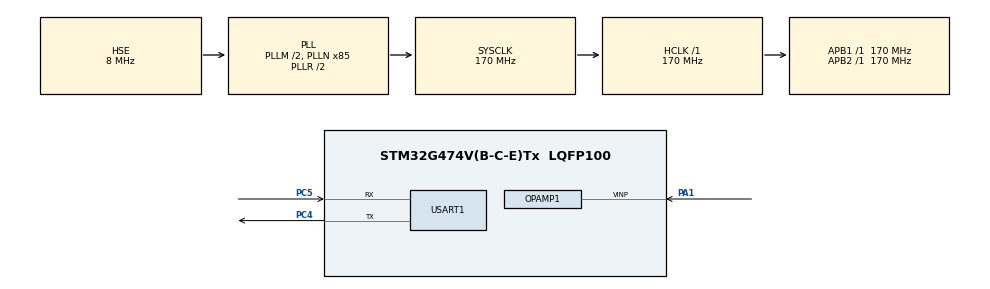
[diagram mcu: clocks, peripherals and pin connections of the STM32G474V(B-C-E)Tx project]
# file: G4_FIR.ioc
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ADC1.Channel-0\#ChannelRegularConversion=ADC_CHANNEL_VOPAMP1
ADC1.DMAContinuousRequests=ENABLE
ADC1.ExternalTrigConv=ADC_EXTERNALTRIG_T3_TRGO
ADC1.NbrOfConversionFlag=1
ADC1.OffsetNumber-0\#ChannelRegularConversion=ADC_OFFSET_NONE
ADC1.Rank-0\#ChannelRegularConversion=1
ADC1.SamplingTime-0\#ChannelRegularConversion=ADC_SAMPLETIME_2CYCLES_5
ADC1.master=1
Dma.ADC1.0.Direction=DMA_PERIPH_TO_MEMORY
Dma.ADC1.0.EventEnable=DISABLE
Dma.ADC1.0.Instance=DMA1_Channel1
Dma.ADC1.0.MemDataAlignment=DMA_MDATAALIGN_HALFWORD
Dma.ADC1.0.MemInc=DMA_MINC_ENABLE
Dma.ADC1.0.Mode=DMA_NORMAL
Dma.ADC1.0.PeriphDataAlignment=DMA_PDATAALIGN_HALFWORD
Dma.ADC1.0.PeriphInc=DMA_PINC_DISABLE
Dma.ADC1.0.Polarity=HAL_DMAMUX_REQ_GEN_RISING
Dma.ADC1.0.Priority=DMA_PRIORITY_LOW
Dma.ADC1.0.RequestNumber=1
Dma.ADC1.0.SignalID=NONE
Dma.ADC1.0.SyncEnable=DISABLE
Dma.ADC1.0.SyncPolarity=HAL_DMAMUX_SYNC_NO_EVENT
Dma.ADC1.0.SyncRequestNumber=1
Dma.ADC1.0.SyncSignalID=NONE
Dma.Request0=ADC1
Mcu.Family=STM32G4
Mcu.Name=STM32G474V(B-C-E)Tx
Mcu.Package=LQFP100
NVIC.DMA1_Channel1_IRQn=true\:0\:0\:false\:false\:true\:false\:true
NVIC.PriorityGroup=NVIC_PRIORITYGROUP_4
PA1.Mode=Follower_Internally_Connected
PA1.Signal=OPAMP1_VINP
PA13.Mode=Serial_Wire
PA13.Signal=SYS_JTMS-SWDIO
PA14.Mode=Serial_Wire
PA14.Signal=SYS_JTCK-SWCLK
PC14-OSC32_IN.Mode=LSE-External-Oscillator
PC14-OSC32_IN.Signal=RCC_OSC32_IN
PC15-OSC32_OUT.Mode=LSE-External-Oscillator
PC15-OSC32_OUT.Signal=RCC_OSC32_OUT
PC4.Mode=Asynchronous
PC4.Signal=USART1_TX
PC5.Mode=Asynchronous
PC5.Signal=USART1_RX
PF0-OSC_IN.Mode=HSE-External-Oscillator
PF0-OSC_IN.Signal=RCC_OSC_IN
PF1-OSC_OUT.Mode=HSE-External-Oscillator
PF1-OSC_OUT.Signal=RCC_OSC_OUT
ProjectManager.HeapSize=0x200
ProjectManager.StackSize=0x400
ProjectManager.TargetToolchain=MDK-ARM V5.32
RCC.ADC12Freq_Value=170000000
RCC.ADC345Freq_Value=170000000
RCC.AHBFreq_Value=170000000
RCC.APB1Freq_Value=170000000
RCC.APB1TimFreq_Value=170000000
RCC.APB2Freq_Value=170000000
RCC.APB2TimFreq_Value=170000000
RCC.CortexFreq_Value=170000000
RCC.EXTERNAL_CLOCK_VALUE=12288000
RCC.HCLKFreq_Value=170000000
RCC.HSE_VALUE=8000000
RCC.HSI48_VALUE=48000000
RCC.HSI_VALUE=16000000
RCC.PLLM=RCC_PLLM_DIV2
RCC.PLLN=85
RCC.PLLSourceVirtual=RCC_PLLSOURCE_HSE
RCC.SYSCLKFreq_VALUE=170000000
RCC.SYSCLKSource=RCC_SYSCLKSOURCE_PLLCLK
RCC.USBFreq_Value=170000000
RCC.VCOOutputFreq_Value=340000000
STMicroelectronics.X-CUBE-ALGOBUILD.1.3.0.LibraryCcDSPOoLibraryJjDSPOoLibrary=true
TIM3.AutoReloadPreload=TIM_AUTORELOAD_PRELOAD_ENABLE
TIM3.PeriodNoDither=1
TIM3.TIM_MasterOutputTrigger=TIM_TRGO_UPDATE
USART1.VirtualMode-Asynchronous=VM_ASYNC
VP_ADC1_OPAMP_INTERNAL1.Mode=IN-OPAMP1
VP_STMicroelectronics.X-CUBE-ALGOBUILD_VS_DSPOoLibraryJjLibrary_1.3.0_1.3.0.Mode=DSPOoLibraryJjLibrary
VP_SYS_VS_DBSignals.Mode=DisableDeadBatterySignals
VP_TIM3_VS_ClockSourceINT.Mode=Internal
board=custom

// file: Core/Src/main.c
/* USER CODE BEGIN Header */
/**
  ******************************************************************************
  * @file           : main.c
  * @brief          : Main program body
  ******************************************************************************
  * @attention
  *
  * Copyright (c) 2022 STMicroelectronics.
  * All rights reserved.
  *
  * This software is licensed under terms that can be found in the LICENSE file
  * in the root directory of this software component.
  * If no LICENSE file comes with this software, it is provided AS-IS.
  *
  ******************************************************************************
  */
/* USER CODE END Header */
#include "main.h"
#include "adc.h"
#include "dma.h"
#include "opamp.h"
#include "tim.h"
#include "usart.h"
#include "gpio.h"

/* USER CODE BEGIN Includes */

#include "arm_math.h"
#include <stdio.h>
#include "delay.h"
#include "string.h"

/* USER CODE END Includes */

void SystemClock_Config(void);
/* USER CODE BEGIN PFP */
void uspp(uint16_t usa,char words[]);

/* USER CODE END PFP */

/* USER CODE BEGIN 0 */

float32_t DATA_IN[5000],DATA_INB[5000];
float32_t DATA_OUT[5000];
uint16_t DATA[5000];
char buffer[10];
int i;

arm_fir_instance_f32 S;

const float32_t B[101] = {
   0.001416345223328, 0.001435384422246, 0.001486642035499, 0.001570116626859,
   0.001685670771667, 0.001833031141338, 0.002011789176834, 0.002221402350021,
   0.002461196009159, 0.002730365802191, 0.003027980668889, 0.003352986390318,
   0.003704209681613, 0.004080362811548, 0.004480048730026, 0.004901766682266,
   0.005343918286277, 0.005804814048062, 0.006282680286986, 0.006775666441868,
   0.007281852726575, 0.007799258102288, 0.008325848532123, 0.008859545482467,
   0.009398234634226, 0.009939774766166,  0.01048200677172,  0.01102276276991,
     0.0115598752707,  0.01209118635454,    0.012614556826,  0.01312787530131,
     0.0136290671898,  0.01411610352987,  0.01458700964048,  0.01503987355008,
     0.0154728541657,  0.01588418914636,  0.01627220244564,  0.01663531149046,
    0.01697203396399,   0.0172809941628,  0.01756092890008,  0.01781069292876,
     0.0180292638604,  0.01821574655821,   0.0183693769845,  0.01848952548564,
    0.01857569949985,  0.01862754567586,  0.01864485139299,  0.01862754567586,
    0.01857569949985,  0.01848952548564,   0.0183693769845,  0.01821574655821,
     0.0180292638604,  0.01781069292876,  0.01756092890008,   0.0172809941628,
    0.01697203396399,  0.01663531149046,  0.01627220244564,  0.01588418914636,
     0.0154728541657,  0.01503987355008,  0.01458700964048,  0.01411610352987,
     0.0136290671898,  0.01312787530131,    0.012614556826,  0.01209118635454,
     0.0115598752707,  0.01102276276991,  0.01048200677172, 0.009939774766166,
   0.009398234634226, 0.008859545482467, 0.008325848532123, 0.007799258102288,
   0.007281852726575, 0.006775666441868, 0.006282680286986, 0.005804814048062,
   0.005343918286277, 0.004901766682266, 0.004480048730026, 0.004080362811548,
   0.003704209681613, 0.003352986390318, 0.003027980668889, 0.002730365802191,
   0.002461196009159, 0.002221402350021, 0.002011789176834, 0.001833031141338,
   0.001685670771667, 0.001570116626859, 0.001486642035499, 0.001435384422246,
   0.001416345223328
};

const int BL = 101;
float32_t pState[10000];

/* USER CODE END 0 */

int main(void)
{

  /* MCU Configuration--------------------------------------------------------*/

  /* Reset of all peripherals, Initializes the Flash interface and the Systick. */
  HAL_Init();

  /* Configure the system clock */
  SystemClock_Config();

  /* Initialize all configured peripherals */
  MX_GPIO_Init();
  MX_DMA_Init();
  MX_ADC1_Init();
  MX_OPAMP1_Init();
  MX_TIM3_Init();
  MX_USART1_UART_Init();
  /* USER CODE BEGIN 2 */

	Delay_Init(170);
	HAL_OPAMP_Start(&hopamp1);
	HAL_TIM_Base_Start(&htim3);
	HAL_ADC_Start_DMA(&hadc1,(uint32_t *)DATA,5000);
	Delay_ms(2000);
	for(i=0;i<5000;i++){
		DATA_IN[i]=((float32_t)DATA[i])/4095.0*3.3;
		sprintf(buffer,"%.2f",DATA_IN[i]*1000);
		uspp(1,buffer);
		uspp(1,"\r\n");
	}

	arm_fir_init_f32(&S, 101, (float32_t *)B, pState, 5000);//numtap:The order of the filter. blockSize:number of data
	arm_fir_f32(&S, DATA_IN , DATA_OUT , 5000);
	//DATA_IN[90]
	for(i=0;i<5000;i++){
		sprintf(buffer,"%.2f",DATA_OUT[i]*1000);
		uspp(1,buffer);
		uspp(1,"\r\n");
	}

  /* USER CODE END 2 */

  /* Infinite loop */
  while (1)
  {

  }
}

void SystemClock_Config(void)
{
  RCC_OscInitTypeDef RCC_OscInitStruct = {0};
  RCC_ClkInitTypeDef RCC_ClkInitStruct = {0};

  /** Configure the main internal regulator output voltage
  */
  HAL_PWREx_ControlVoltageScaling(PWR_REGULATOR_VOLTAGE_SCALE1_BOOST);
  /** Initializes the RCC Oscillators according to the specified parameters
  * in the RCC_OscInitTypeDef structure.
  */
  RCC_OscInitStruct.OscillatorType = RCC_OSCILLATORTYPE_HSE;
  RCC_OscInitStruct.HSEState = RCC_HSE_ON;
  RCC_OscInitStruct.PLL.PLLState = RCC_PLL_ON;
  RCC_OscInitStruct.PLL.PLLSource = RCC_PLLSOURCE_HSE;
  RCC_OscInitStruct.PLL.PLLM = RCC_PLLM_DIV2;
  RCC_OscInitStruct.PLL.PLLN = 85;
  RCC_OscInitStruct.PLL.PLLP = RCC_PLLP_DIV2;
  RCC_OscInitStruct.PLL.PLLQ = RCC_PLLQ_DIV2;
  RCC_OscInitStruct.PLL.PLLR = RCC_PLLR_DIV2;
  if (HAL_RCC_OscConfig(&RCC_OscInitStruct) != HAL_OK)
  {
    Error_Handler();
  }
  /** Initializes the CPU, AHB and APB buses clocks
  */
  RCC_ClkInitStruct.ClockType = RCC_CLOCKTYPE_HCLK|RCC_CLOCKTYPE_SYSCLK
                              |RCC_CLOCKTYPE_PCLK1|RCC_CLOCKTYPE_PCLK2;
  RCC_ClkInitStruct.SYSCLKSource = RCC_SYSCLKSOURCE_PLLCLK;
  RCC_ClkInitStruct.AHBCLKDivider = RCC_SYSCLK_DIV1;
  RCC_ClkInitStruct.APB1CLKDivider = RCC_HCLK_DIV1;
  RCC_ClkInitStruct.APB2CLKDivider = RCC_HCLK_DIV1;

  if (HAL_RCC_ClockConfig(&RCC_ClkInitStruct, FLASH_LATENCY_4) != HAL_OK)
  {
    Error_Handler();
  }
}

/* USER CODE BEGIN 4 */

void uspp(uint16_t usa,char words[]){
	int len;
	len=strlen((const char*)words);

	if(usa==1){
		HAL_UART_Transmit(&huart1,(uint8_t*)words,len,0xffff);
	}

}

/* USER CODE END 4 */

void Error_Handler(void)
{
  __disable_irq();
  while (1)
  {
  }
}
